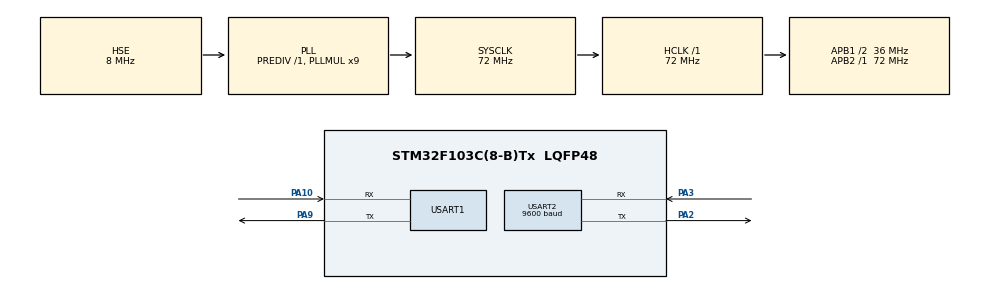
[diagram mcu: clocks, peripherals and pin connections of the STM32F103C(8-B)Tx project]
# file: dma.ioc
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Dma.Request0=USART1_RX
Dma.Request1=USART2_RX
Dma.USART1_RX.0.Direction=DMA_PERIPH_TO_MEMORY
Dma.USART1_RX.0.Instance=DMA1_Channel5
Dma.USART1_RX.0.MemDataAlignment=DMA_MDATAALIGN_BYTE
Dma.USART1_RX.0.MemInc=DMA_MINC_ENABLE
Dma.USART1_RX.0.Mode=DMA_NORMAL
Dma.USART1_RX.0.PeriphDataAlignment=DMA_PDATAALIGN_BYTE
Dma.USART1_RX.0.PeriphInc=DMA_PINC_DISABLE
Dma.USART1_RX.0.Priority=DMA_PRIORITY_LOW
Dma.USART2_RX.1.Direction=DMA_PERIPH_TO_MEMORY
Dma.USART2_RX.1.Instance=DMA1_Channel6
Dma.USART2_RX.1.MemDataAlignment=DMA_MDATAALIGN_BYTE
Dma.USART2_RX.1.MemInc=DMA_MINC_ENABLE
Dma.USART2_RX.1.Mode=DMA_NORMAL
Dma.USART2_RX.1.PeriphDataAlignment=DMA_PDATAALIGN_BYTE
Dma.USART2_RX.1.PeriphInc=DMA_PINC_DISABLE
Dma.USART2_RX.1.Priority=DMA_PRIORITY_LOW
Mcu.Family=STM32F1
Mcu.Name=STM32F103C(8-B)Tx
Mcu.Package=LQFP48
NVIC.DMA1_Channel5_IRQn=true\:0\:0\:false\:false\:true\:false\:true\:true
NVIC.DMA1_Channel6_IRQn=true\:0\:0\:false\:false\:true\:false\:true\:true
NVIC.PriorityGroup=NVIC_PRIORITYGROUP_4
NVIC.USART2_IRQn=true\:0\:0\:false\:false\:true\:true\:true\:true
PA10.Mode=Asynchronous
PA10.Signal=USART1_RX
PA2.Mode=Asynchronous
PA2.Signal=USART2_TX
PA3.Mode=Asynchronous
PA3.Signal=USART2_RX
PA9.Mode=Asynchronous
PA9.Signal=USART1_TX
PD0-OSC_IN.Mode=HSE-External-Oscillator
PD0-OSC_IN.Signal=RCC_OSC_IN
PD1-OSC_OUT.Mode=HSE-External-Oscillator
PD1-OSC_OUT.Signal=RCC_OSC_OUT
ProjectManager.HeapSize=0x200
ProjectManager.StackSize=0x400
ProjectManager.TargetToolchain=MDK-ARM V5.32
RCC.AHBFreq_Value=72000000
RCC.APB1CLKDivider=RCC_HCLK_DIV2
RCC.APB1Freq_Value=36000000
RCC.APB1TimFreq_Value=72000000
RCC.APB2Freq_Value=72000000
RCC.APB2TimFreq_Value=72000000
RCC.HCLKFreq_Value=72000000
RCC.PLLMUL=RCC_PLL_MUL9
RCC.PLLSourceVirtual=RCC_PLLSOURCE_HSE
RCC.SYSCLKFreq_VALUE=72000000
RCC.SYSCLKSource=RCC_SYSCLKSOURCE_PLLCLK
RCC.USBFreq_Value=72000000
USART1.VirtualMode=VM_ASYNC
USART2.BaudRate=9600
USART2.VirtualMode=VM_ASYNC
VP_SYS_VS_ND.Mode=No_Debug
board=custom

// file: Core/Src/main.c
/* USER CODE BEGIN Header */
/**
  ****************************************************************************
  * @file           : main.c
  * @brief          : Main program body
  ****************************************************************************
  * @attention
  *
  * Copyright (c) 2026 STMicroelectronics.
  * All rights reserved.
  *
  * This software is licensed under terms that can be found in the LICENSE file
  * in the root directory of this software component.
  * If no LICENSE file comes with this software, it is provided AS-IS.
  *
  ****************************************************************************
  */
/* USER CODE END Header */
#include "main.h"

UART_HandleTypeDef huart1;
UART_HandleTypeDef huart2;
DMA_HandleTypeDef hdma_usart1_rx;
DMA_HandleTypeDef hdma_usart2_rx;

void SystemClock_Config(void);
static void MX_GPIO_Init(void);
static void MX_DMA_Init(void);
static void MX_USART1_UART_Init(void);
static void MX_USART2_UART_Init(void);

int main(void)
{

  /* USER CODE BEGIN 1 */
	uint8_t rxarrpoll[12]={0};
	uint8_t rxarrinterupt[12]={0};

  /* USER CODE END 1 */

  /* MCU Configuration--------------------------------------------------------*/

  /* Reset of all peripherals, Initializes the Flash interface and the Systick. */
  HAL_Init();

  /* Configure the system clock */
  SystemClock_Config();

  /* Initialize all configured peripherals */
  MX_GPIO_Init();
  MX_DMA_Init();
  MX_USART1_UART_Init();
  MX_USART2_UART_Init();
  /* USER CODE BEGIN 2 */
	HAL_UART_Receive_DMA(&huart1, rxarrpoll, sizeof(rxarrpoll));
	HAL_DMA_PollForTransfer(&hdma_usart1_rx, HAL_DMA_HALF_TRANSFER, HAL_MAX_DELAY);
	HAL_UART_Receive_DMA(&huart2, rxarrinterupt,sizeof(rxarrinterupt));

  /* USER CODE END 2 */

  /* Infinite loop */
  while (1)
  {

  }
}

void SystemClock_Config(void)
{
  RCC_OscInitTypeDef RCC_OscInitStruct = {0};
  RCC_ClkInitTypeDef RCC_ClkInitStruct = {0};

  /** Initializes the RCC Oscillators according to the specified parameters
  * in the RCC_OscInitTypeDef structure.
  */
  RCC_OscInitStruct.OscillatorType = RCC_OSCILLATORTYPE_HSE;
  RCC_OscInitStruct.HSEState = RCC_HSE_ON;
  RCC_OscInitStruct.HSEPredivValue = RCC_HSE_PREDIV_DIV1;
  RCC_OscInitStruct.HSIState = RCC_HSI_ON;
  RCC_OscInitStruct.PLL.PLLState = RCC_PLL_ON;
  RCC_OscInitStruct.PLL.PLLSource = RCC_PLLSOURCE_HSE;
  RCC_OscInitStruct.PLL.PLLMUL = RCC_PLL_MUL9;
  if (HAL_RCC_OscConfig(&RCC_OscInitStruct) != HAL_OK)
  {
    Error_Handler();
  }

  /** Initializes the CPU, AHB and APB buses clocks
  */
  RCC_ClkInitStruct.ClockType = RCC_CLOCKTYPE_HCLK|RCC_CLOCKTYPE_SYSCLK
                              |RCC_CLOCKTYPE_PCLK1|RCC_CLOCKTYPE_PCLK2;
  RCC_ClkInitStruct.SYSCLKSource = RCC_SYSCLKSOURCE_PLLCLK;
  RCC_ClkInitStruct.AHBCLKDivider = RCC_SYSCLK_DIV1;
  RCC_ClkInitStruct.APB1CLKDivider = RCC_HCLK_DIV2;
  RCC_ClkInitStruct.APB2CLKDivider = RCC_HCLK_DIV1;

  if (HAL_RCC_ClockConfig(&RCC_ClkInitStruct, FLASH_LATENCY_2) != HAL_OK)
  {
    Error_Handler();
  }
}

static void MX_USART1_UART_Init(void)
{

  huart1.Instance = USART1;
  huart1.Init.BaudRate = 9600;
  huart1.Init.WordLength = UART_WORDLENGTH_8B;
  huart1.Init.StopBits = UART_STOPBITS_1;
  huart1.Init.Parity = UART_PARITY_NONE;
  huart1.Init.Mode = UART_MODE_TX_RX;
  huart1.Init.HwFlowCtl = UART_HWCONTROL_NONE;
  huart1.Init.OverSampling = UART_OVERSAMPLING_16;
  if (HAL_UART_Init(&huart1) != HAL_OK)
  {
    Error_Handler();
  }

}

static void MX_USART2_UART_Init(void)
{

  huart2.Instance = USART2;
  huart2.Init.BaudRate = 9600;
  huart2.Init.WordLength = UART_WORDLENGTH_8B;
  huart2.Init.StopBits = UART_STOPBITS_1;
  huart2.Init.Parity = UART_PARITY_NONE;
  huart2.Init.Mode = UART_MODE_TX_RX;
  huart2.Init.HwFlowCtl = UART_HWCONTROL_NONE;
  huart2.Init.OverSampling = UART_OVERSAMPLING_16;
  if (HAL_UART_Init(&huart2) != HAL_OK)
  {
    Error_Handler();
  }

}

static void MX_DMA_Init(void)
{

  /* DMA controller clock enable */
  __HAL_RCC_DMA1_CLK_ENABLE();

  /* DMA interrupt init */
  /* DMA1_Channel5_IRQn interrupt configuration */
  HAL_NVIC_SetPriority(DMA1_Channel5_IRQn, 0, 0);
  HAL_NVIC_EnableIRQ(DMA1_Channel5_IRQn);
  /* DMA1_Channel6_IRQn interrupt configuration */
  HAL_NVIC_SetPriority(DMA1_Channel6_IRQn, 0, 0);
  HAL_NVIC_EnableIRQ(DMA1_Channel6_IRQn);

}

static void MX_GPIO_Init(void)
{
  GPIO_InitTypeDef GPIO_InitStruct = {0};

  /* GPIO Ports Clock Enable */
  __HAL_RCC_GPIOD_CLK_ENABLE();
  __HAL_RCC_GPIOA_CLK_ENABLE();

  /*Configure GPIO pin Output Level */
  HAL_GPIO_WritePin(GPIOA, GPIO_PIN_0, GPIO_PIN_RESET);

  /*Configure GPIO pin : PA0 */
  GPIO_InitStruct.Pin = GPIO_PIN_0;
  GPIO_InitStruct.Mode = GPIO_MODE_OUTPUT_PP;
  GPIO_InitStruct.Pull = GPIO_PULLUP;
  GPIO_InitStruct.Speed = GPIO_SPEED_FREQ_LOW;
  HAL_GPIO_Init(GPIOA, &GPIO_InitStruct);

}

/* USER CODE BEGIN 4 */
	void HAL_UART_RxHalfCpltCallback(UART_HandleTypeDef *huart){
		if(huart->Instance == USART2){
			HAL_GPIO_TogglePin(GPIOA,GPIO_PIN_0);
		}
	}

/* USER CODE END 4 */

void Error_Handler(void)
{
  __disable_irq();
  while (1)
  {
  }
}
